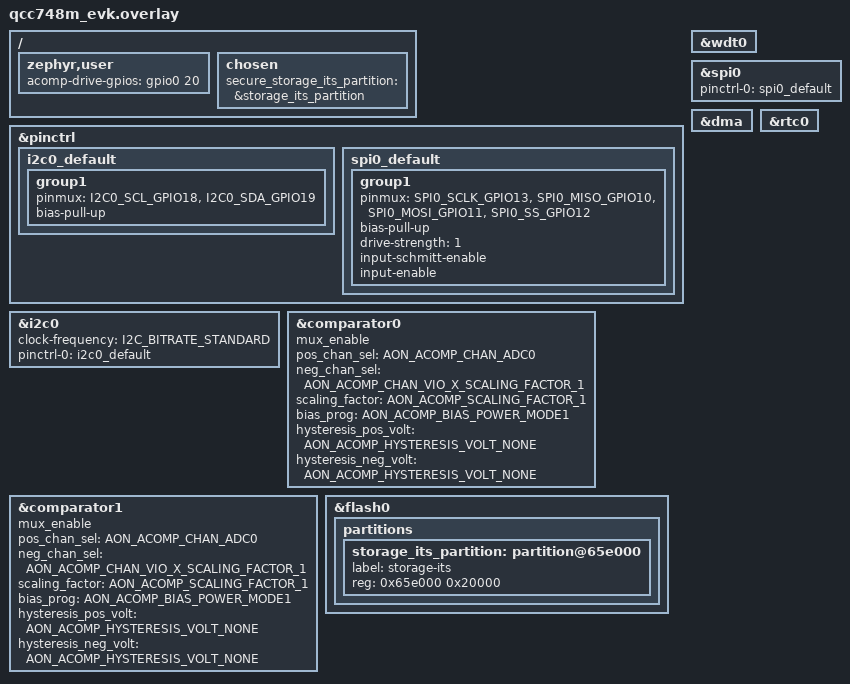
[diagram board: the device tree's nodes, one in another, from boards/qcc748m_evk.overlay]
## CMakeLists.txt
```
# Copyright (c) Qualcomm Technologies, Inc. and/or its subsidiaries
# SPDX-License-Identifier: BSD-3-Clause

cmake_minimum_required(VERSION 3.20.0)

# boards/qcc748m_evk.conf and boards/qcc748m_evk.overlay are auto-detected
# by Zephyr from this project's boards/ directory — no explicit references needed.
# All shell modules (async_test_shell, i2c_eeprom_async, crypto, flash, psram...)
# are provided by qapp/qcc74x/common/shell/ via module.yml auto-inclusion.
find_package(Zephyr REQUIRED HINTS $ENV{ZEPHYR_BASE})
project(qcli_app)

target_sources(app PRIVATE src/main.c)
```

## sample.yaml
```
# Copyright (c) Qualcomm Technologies, Inc. and/or its subsidiaries
# SPDX-License-Identifier: BSD-3-Clause

sample:
  name: QCC74x CLI App
  description: >
    Interactive CLI for QCC74x development boards. Provides shell commands
    for all on-board peripherals (I2C, SPI, CAN, PWM, ADC, DAC, GPIO,
    WDT, RTC, Counter, Comparator, Crypto, Flash, PSRAM) plus WiFi/Net.

tests:
  sample.qcli_app:
    platform_allow:
      - qcc748m_evk/qcc748
    harness: console
    harness_config:
      type: one_line
      regex:
        - "qcc74x:~\\$"
    timeout: 60
    tags:
      - shell
      - qcli_app
```

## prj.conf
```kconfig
# Copyright (c) Qualcomm Technologies, Inc. and/or its subsidiaries
# SPDX-License-Identifier: BSD-3-Clause
#
# qcli minimal conf — networking and peripheral config 
CONFIG_EARLY_CONSOLE=y

# Common shell and SPI shell support
CONFIG_SHELL=y
CONFIG_SHELL_BACKEND_SERIAL=y
CONFIG_QCOM_SPI_SHELL=y
CONFIG_SPI=y
CONFIG_SPI_SLAVE=y
```

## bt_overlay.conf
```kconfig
CONFIG_SYSTEM_WORKQUEUE_STACK_SIZE=2048
CONFIG_TEST=y
CONFIG_TEST_LOGGING_DEFAULTS=n
CONFIG_BT=y
CONFIG_LOG=y
CONFIG_BT_CENTRAL=y
CONFIG_BT_PERIPHERAL=y
CONFIG_BT_PRIVACY=y
CONFIG_BT_SMP=y
CONFIG_BT_PASSKEY_KEYPRESS=y
CONFIG_BT_APP_PASSKEY=y
CONFIG_BT_ATT_PREPARE_COUNT=2
CONFIG_BT_GATT_CLIENT=y
CONFIG_BT_L2CAP_DYNAMIC_CHANNEL=y
CONFIG_BT_SHELL=y
CONFIG_BT_DEVICE_NAME="test shell"
CONFIG_BT_DEVICE_NAME_DYNAMIC=y
CONFIG_BT_L2CAP_TX_BUF_COUNT=4
CONFIG_BT_ID_MAX=2
CONFIG_BT_EATT=y
CONFIG_BT_L2CAP_ECRED=y
CONFIG_BT_GATT_DYNAMIC_DB=y
CONFIG_BT_GATT_NOTIFY_MULTIPLE=y
CONFIG_BT_HRS=y
CONFIG_BT_FILTER_ACCEPT_LIST=y
CONFIG_BT_REMOTE_INFO=y
CONFIG_BT_REMOTE_VERSION=y
CONFIG_BT_GATT_AUTO_DISCOVER_CCC=y

CONFIG_BT_SETTINGS=y
CONFIG_FLASH=y
CONFIG_FLASH_MAP=y
CONFIG_NVS=y
CONFIG_SETTINGS=y

CONFIG_BT_EXT_ADV=y
CONFIG_BT_EXT_ADV_LEGACY_SUPPORT=y
CONFIG_BT_PER_ADV=y
CONFIG_BT_PER_ADV_SYNC=y

CONFIG_BT_USER_DATA_LEN_UPDATE=y
CONFIG_BT_AUTO_DATA_LEN_UPDATE=y

CONFIG_BT_EAD=y

CONFIG_BT_USER_PHY_UPDATE=y

CONFIG_BT_ISO_BROADCASTER=y
CONFIG_BT_ISO_SYNC_RECEIVER=y
CONFIG_BT_ISO_CENTRAL=y
CONFIG_BT_ISO_PERIPHERAL=y

CONFIG_LOG_RUNTIME_FILTERING=y

CONFIG_MINIMAL_LIBC_STRING_ERROR_TABLE=y
CONFIG_QCOM_ACOMP_SHELL=n
CONFIG_PSA_CRYPTO_ENABLE_ALL=n

CONFIG_BT_RX_STACK_SIZE=2048

# PSRAM: enable 4MB PSRAM with code-copy support on qcc748.
CONFIG_FLASH_XIP_LENGTH=0x400000
CONFIG_PSRAM=y
CONFIG_PSRAM_LENGTH=0x400000
CONFIG_PSRAM_COPY_CODE=y
```

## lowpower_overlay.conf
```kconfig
# Copyright (c) Qualcomm Technologies, Inc. and/or its subsidiaries
# SPDX-License-Identifier: BSD-3-Clause

# Default QCC748 Wi-Fi PDS15/LPFW profile for QCLI.
CONFIG_PM=y
CONFIG_PM_POLICY_CUSTOM=y
CONFIG_PM_CPU_SHELL=y
CONFIG_PM_DEVICE=y
CONFIG_PM_NEED_ALL_DEVICES_IDLE=n
CONFIG_PM_DEVICE_SYSTEM_MANAGED=y
CONFIG_GPIO=y
CONFIG_PSRAM=n
CONFIG_RISCV_MACHINE_TIMER=n
CONFIG_QCC74X_PM_PDS15=y

CONFIG_POWEROFF=y
CONFIG_QCC74X_HBN_SHELL=y
CONFIG_QCC74X_WIFI_LOW_POWER=y
CONFIG_QCC74X_PM_DIAGNOSTICS=y
CONFIG_QCC74X_PM_PDS15_LOG_LEVEL_OFF=y
CONFIG_QCC74X_PM_PDS_VALIDATION=y

CONFIG_THREAD_LOCAL_STORAGE=y
CONFIG_CURRENT_THREAD_USE_TLS=y
CONFIG_SHELL_PROMPT_UART="qcc74x:~$"
CONFIG_LOG_MODE_DEFERRED=y
CONFIG_LOG_RUNTIME_FILTERING=n
CONFIG_PRINTK=y
CONFIG_HEAP_MEM_POOL_SIZE=26624

# PDS15 has no PSRAM. Keep Wi-Fi runtime allocations within OCRAM/WRAM.
CONFIG_NET_PKT_TX_COUNT=14
CONFIG_NET_BUF_TX_COUNT=16
```

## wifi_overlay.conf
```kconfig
# ==================== Base (from wifi-shell prj.conf) ====================
CONFIG_EARLY_CONSOLE=y
CONFIG_NETWORKING=y
CONFIG_TEST_RANDOM_GENERATOR=y


CONFIG_NET_MAX_CONTEXTS=10
CONFIG_NET_DHCPV4=y

CONFIG_NET_IPV4=y
CONFIG_NET_TCP=y
CONFIG_NET_SHELL=y
CONFIG_NET_STATISTICS=y
CONFIG_NET_STATISTICS_PERIODIC_OUTPUT=n

CONFIG_WIFI=y
CONFIG_WIFI_LOG_LEVEL_ERR=y
CONFIG_NET_L2_WIFI_SHELL=y
CONFIG_NET_MGMT_EVENT_QUEUE_TIMEOUT=5000

# ==================== Network Buffers & Interfaces ====================
# Number of RX packets
CONFIG_NET_PKT_RX_COUNT=8
# Number of TX packets
CONFIG_NET_PKT_TX_COUNT=14
# Network buffer pool size (RX)
CONFIG_NET_BUF_RX_COUNT=8
# Network buffer pool size (TX)
CONFIG_NET_BUF_TX_COUNT=16
# Max IPv4 addresses per interface
CONFIG_NET_IF_MAX_IPV4_COUNT=2
# Max IPv6 addresses per interface
CONFIG_NET_IF_MAX_IPV6_COUNT=2
# Enable Ethernet L2
CONFIG_NET_L2_ETHERNET=y
CONFIG_NET_BUF_DATA_SIZE=1600
CONFIG_NET_BUF_POOL_USAGE=y
CONFIG_NET_BUF_LOG=y

CONFIG_NET_TX_STACK_SIZE=4096
CONFIG_NET_RX_STACK_SIZE=4096

CONFIG_NET_TCP_WORKQ_STACK_SIZE=2048
# ==================== Network Management ====================
# Net management event queue size
CONFIG_NET_MGMT_EVENT_QUEUE_SIZE=10
# Net management event handler stack size
CONFIG_NET_MGMT_EVENT_STACK_SIZE=8192
# Enable network connection manager
CONFIG_NET_CONNECTION_MANAGER=y
CONFIG_NET_CONNECTION_MANAGER_MONITOR_STACK_SIZE=2048

# ==================== Ethernet Driver ====================
# Keep the WiFi shell sample off the EMAC path for now.
# CONFIG_ETH_DRIVER is not set
# CONFIG_ETH_PHY_DRIVER is not set

# ==================== IPv4 & DHCPv4 ====================
# Number of DHCPv4 server addresses
CONFIG_NET_DHCPV4_SERVER_ADDR_COUNT=4
# ICMP probe timeout for DHCPv4 (ms)
CONFIG_NET_DHCPV4_SERVER_ICMP_PROBE_TIMEOUT=1000
# Enable DHCPv4 server
CONFIG_NET_DHCPV4_SERVER=y
# Enable DHCPv4 DNS address option
CONFIG_NET_DHCPV4_OPTION_DNS_ADDRESS=y
# DHCPv4 server log level: debug
CONFIG_NET_DHCPV4_SERVER_LOG_LEVEL_DBG=y

# ==================== IPv6 & DHCPv6 ====================
# Enable IPv6 protocol
CONFIG_NET_IPV6=y
# Enable RDNSS option in IPv6 RA
CONFIG_NET_IPV6_RA_RDNSS=y
# Enable DHCPv6 DNS address option
CONFIG_NET_DHCPV6_OPTION_DNS_ADDRESS=y

# ==================== Sockets & TLS/DTLS ====================
# Keep the sample on the plain sockets path on Zephyr 4.3.
# CONFIG_NET_SOCKETS_SOCKOPT_TLS is not set
# CONFIG_NET_SOCKETS_ENABLE_DTLS is not set
# DNS query timeout (ms)
CONFIG_NET_SOCKETS_DNS_TIMEOUT=2000
# DNS backoff interval (ms)
CONFIG_NET_SOCKETS_DNS_BACKOFF_INTERVAL=5000
# Enable Sockets service
CONFIG_NET_SOCKETS_SERVICE=y
# Service thread priority
CONFIG_NET_SOCKETS_SERVICE_THREAD_PRIO=15
# Service thread stack size
CONFIG_NET_SOCKETS_SERVICE_STACK_SIZE=4096

# ==================== DNS Resolver ====================
CONFIG_DNS_RESOLVER=y

# ==================== Network Test Tool ====================
# Enable zperf performance testing
CONFIG_NET_ZPERF=y
CONFIG_NET_ZPERF_SERVER=y
CONFIG_NET_ZPERF_MAX_SESSIONS=6
CONFIG_ZPERF_SESSION_PER_THREAD=y
CONFIG_ZPERF_WORK_Q_STACK_SIZE=4096
CONFIG_NET_ZPERF_MAX_PACKET_SIZE=1500

# ==================== Statistics ====================
# Enable named statistics
CONFIG_STATS_NAMES=y
# Enable stats in shell
CONFIG_STATS_SHELL=y
# Enable statistics
CONFIG_STATS=y
# Enable network statistics shell commands
CONFIG_NET_STATISTICS_USER_API=y

# ==================== WiFi Configuration ====================
# QCC74X WiFi driver
CONFIG_WIFI_QCC74X=y
# AP & STA mode support
CONFIG_QC7XX_WIFI_AP_STA_MODE=y
# STA mode auto DHCPv4
CONFIG_QC7XX_WIFI_STA_AUTO_DHCPV4=y
# WiFi network manager
CONFIG_WIFI_NM=y
# Max managed interfaces
CONFIG_WIFI_NM_MAX_MANAGED_INTERFACES=4
# Shell max AP/STA interfaces
CONFIG_WIFI_SHELL_MAX_AP_STA=4
```

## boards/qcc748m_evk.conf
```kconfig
# Copyright (c) Qualcomm Technologies, Inc. and/or its subsidiaries
# SPDX-License-Identifier: BSD-3-Clause
#
# qcc748m_evk board configuration for qcli.
# Merged from wifi-shell prj.conf + boards/qcc748m_evk.conf.


# ==================== Shell Configuration ====================
# Stack size for shell task
CONFIG_SHELL_STACK_SIZE=3072
# QCOM comparator shell validation
CONFIG_COMPARATOR=y
CONFIG_QCOM_ACOMP_SHELL=y
# Reopen / startup on this bench can deliver a short RX burst before the shell
# thread drains input, so keep more headroom than the generic default (64).
CONFIG_SHELL_BACKEND_SERIAL_RX_RING_BUFFER_SIZE=128
# Shell prompt setting
CONFIG_SHELL_PROMPT_UART="qcc74x:~$"
#not defined yet
#CONFIG_ETH_QC7XX_EMAC=n


# ==================== Threads & Workqueue ====================
# Main stack size
CONFIG_MAIN_STACK_SIZE=4096
# System workqueue stack size
CONFIG_SYSTEM_WORKQUEUE_STACK_SIZE=6144
# Dynamic threads support
CONFIG_DYNAMIC_THREAD=y
CONFIG_DYNAMIC_THREAD_ALLOC=y
CONFIG_DYNAMIC_THREAD_PREFER_POOL=y
# Runtime statistics
CONFIG_THREAD_RUNTIME_STATS=y
CONFIG_THREAD_RUNTIME_STATS_USE_TIMING_FUNCTIONS=y
# Thread info & monitoring
CONFIG_THREAD_STACK_INFO=y
CONFIG_THREAD_MONITOR=y
CONFIG_THREAD_NAME=y
CONFIG_THREAD_CUSTOM_DATA=y
# Initialize all thread stacks
CONFIG_INIT_STACKS=y

# ==================== Memory & Heap ====================
# Heap memory pool size
CONFIG_HEAP_MEM_POOL_SIZE=32708
# Sys heap runtime stats
CONFIG_SYS_HEAP_RUNTIME_STATS=y
# Shared multi-heap support
CONFIG_SHARED_MULTI_HEAP=y
# ==================== mbedTLS / PSA Crypto ====================
# Zephyr 4.3 moved most legacy mbedTLS feature toggles behind PSA wants.
# Keep TLS sockets disabled above, but still link the crypto pieces used
# by the QC7XX wireless HAL blob.
CONFIG_MBEDTLS=y
# Use QCC74x soc_multi_heap via mbedtls_platform_set_calloc_free().
# CONFIG_MBEDTLS_ENABLE_HEAP is not set
CONFIG_MBEDTLS_PSA_STATIC_KEY_SLOTS=n
CONFIG_PSA_CRYPTO=y
CONFIG_PSA_CRYPTO_PROVIDER_MBEDTLS=y
CONFIG_PSA_WANT_KEY_TYPE_ECC_PUBLIC_KEY=y
CONFIG_PSA_WANT_ECC_SECP_R1_256=y
CONFIG_PSA_WANT_ALG_ECDH=y
CONFIG_PSA_WANT_ALG_ECDSA=y
CONFIG_PSA_WANT_KEY_TYPE_AES=y
CONFIG_PSA_WANT_ALG_ECB_NO_PADDING=y
CONFIG_MBEDTLS_ASN1_PARSE_C=y
CONFIG_MBEDTLS_MD_C=y
CONFIG_MBEDTLS_ENTROPY_C=y
CONFIG_MBEDTLS_CTR_DRBG_C=y
CONFIG_MBEDTLS_PSA_CRYPTO_LEGACY_RNG=y
CONFIG_MBEDTLS_PK_WRITE_C=y
CONFIG_MBEDTLS_PKCS5_C=y
CONFIG_MBEDTLS_PEM_PARSE_C=y
CONFIG_MBEDTLS_ECP_NIST_OPTIM=y
CONFIG_MBEDTLS_AES_ROM_TABLES=y

# ==================== CRC & File System ====================
CONFIG_CRC=y
CONFIG_ZVFS_POLL_MAX=15

# ==================== Logging & Commands ====================
CONFIG_LOG=y
# Enable log commands
CONFIG_LOG_CMDS=y
CONFIG_NET_LOG=y

CONFIG_NET_CONFIG_LOG_LEVEL_DBG=y

# ==================== QCC748M Coredump Profiles ====================
# Common support for every mode. Keep these settings enabled when switching
# profiles: the QCC74x runtime performs the post-dump software reset.
CONFIG_DEBUG_COREDUMP=y
CONFIG_QCC74X_COREDUMP_RUNTIME=y
CONFIG_QCC74X_COREDUMP_AUTO_RESET=y
CONFIG_QCC74X_COREDUMP_TEST_COMMANDS=y
#
# Select exactly one mode below. Mode 0 is the default.
#
# MODE 0 (default): Zephyr native minimal coredump through the normal logging
# backend. It preserves Zephyr's basic payload and resets after output drains.
CONFIG_DEBUG_COREDUMP_BACKEND_LOGGING=y
CONFIG_DEBUG_COREDUMP_MEMORY_DUMP_MIN=y
#
# To select Mode 1, 2, or 3: comment out the two active MODE 0 settings above,
# then uncomment all settings in exactly one block below. Do not change the
# common support settings.
#
# MODE 1: serial_full_psram
# Full OCRAM/WRAM/PSRAM dump through the safe serial backend. For practical
# full-PSRAM capture, also enable the optional 2 Mbaud UART0 overlay block.
# CONFIG_DEBUG_COREDUMP_BACKEND_OTHER=y
# CONFIG_DEBUG_COREDUMP_MEMORY_DUMP_LINKER_RAM=y
# CONFIG_PSRAM_LENGTH=0x800000
# CONFIG_QCC74X_COREDUMP_FULL_MEMORY=y
# CONFIG_QCC74X_COREDUMP_OTHER_SAFE_SERIAL=y
# CONFIG_QCC74X_COREDUMP_SERIAL_FULL_PSRAM=y
#
# MODE 2: flash_tracked_psram
# Full static RAM plus tracked active PSRAM allocations stored in the 1.5 MiB
# coredump Flash partition. Also enable the Mode 2 Flash partition overlay.
# CONFIG_FLASH=y
# CONFIG_DEBUG_COREDUMP_BACKEND_OTHER=y
# CONFIG_DEBUG_COREDUMP_MEMORY_DUMP_LINKER_RAM=y
# CONFIG_PSRAM_LENGTH=0x800000
# CONFIG_QCC74X_COREDUMP_FULL_MEMORY=y
# CONFIG_QCC74X_COREDUMP_OTHER_SAFE_FLASH=y
# CONFIG_QCC74X_COREDUMP_SERIAL_TRACKED_PSRAM=y
#
# MODE 3: serial_tracked_psram
# Full static RAM plus tracked active PSRAM allocations through the safe
# serial backend at the normal console baud rate.
# CONFIG_DEBUG_COREDUMP_BACKEND_OTHER=y
# CONFIG_DEBUG_COREDUMP_MEMORY_DUMP_LINKER_RAM=y
# CONFIG_PSRAM_LENGTH=0x800000
# CONFIG_QCC74X_COREDUMP_FULL_MEMORY=y
# CONFIG_QCC74X_COREDUMP_OTHER_SAFE_SERIAL=y
# CONFIG_QCC74X_COREDUMP_SERIAL_TRACKED_PSRAM=y
#
# `qcom coredump ...` shell support is selected automatically by the QCC74x
# runtime. Zephyr's independent CONFIG_DEBUG_COREDUMP_SHELL is not required.
# The following generic debug features remain available independently of
# coredump and are intentionally not part of any coredump profile.
CONFIG_SYMTAB=y
CONFIG_SYMTAB_SHELL=y
CONFIG_TRACING=y
CONFIG_DEBUG_THREAD_INFO=n
CONFIG_THREAD_ANALYZER=y

# ==================== POSIX Support ====================
CONFIG_POSIX_API=y
CONFIG_POSIX_TIMERS=y
CONFIG_REQUIRES_FLOAT_PRINTF=y
CONFIG_PICOLIBC_IO_FLOAT=y

# ==================== Miscellaneous ====================
# Reboot support
CONFIG_REBOOT=y

# Watchdog support: expose the native Zephyr WDT shell for diagnosis.
CONFIG_WATCHDOG=y
CONFIG_WDT_SHELL=y
CONFIG_WDT_DISABLE_AT_BOOT=n

# Kernel / PM / HW Info
CONFIG_KERNEL_SHELL=y
CONFIG_HWINFO=y
CONFIG_HWINFO_SHELL=y
# Settings
CONFIG_SETTINGS=y
CONFIG_SETTINGS_SHELL=y


# ==================== Peripheral Shells ====================
# Async shell execution
CONFIG_QCOM_SHELL_ASYNC=y
CONFIG_SHELL_ASYNC_STACK_SIZE=2048

# I2C
CONFIG_I2C=y
CONFIG_QCOM_I2C_SHELL=y

# RTC
CONFIG_RTC=y
CONFIG_RTC_SHELL=y

# ==================== Secure Storage (PSA ITS) ====================
CONFIG_SECURE_STORAGE=y
CONFIG_SECURE_STORAGE_ITS_IMPLEMENTATION_ZEPHYR=y
CONFIG_SECURE_STORAGE_ITS_STORE_IMPLEMENTATION_ZMS=y
CONFIG_SECURE_STORAGE_ITS_TRANSFORM_MODULE=y
CONFIG_SECURE_STORAGE_ITS_TRANSFORM_IMPLEMENTATION_AEAD=y
CONFIG_SECURE_STORAGE_ITS_TRANSFORM_AEAD_SCHEME_AES_GCM=y
CONFIG_SECURE_STORAGE_ITS_TRANSFORM_AEAD_KEY_PROVIDER_ENTRY_UID_HASH=y
CONFIG_SECURE_STORAGE_ITS_TRANSFORM_AEAD_NONCE_PROVIDER_DEFAULT=y
CONFIG_SECURE_STORAGE_ITS_TRANSFORM_AEAD_KEY_SIZE=32
CONFIG_SECURE_STORAGE_ITS_TRANSFORM_AEAD_NONCE_SIZE=12
CONFIG_SECURE_STORAGE_ITS_MAX_DATA_SIZE=128
CONFIG_ZMS=y
CONFIG_FLASH=y
CONFIG_FLASH_MAP=y
CONFIG_SOC_FLASH_QCC74X=y
```

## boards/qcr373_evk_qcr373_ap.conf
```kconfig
# Copyright (c) Qualcomm Technologies, Inc. and/or its subsidiaries
# SPDX-License-Identifier: BSD-3-Clause

CONFIG_SHELL=y
CONFIG_SHELL_MINIMAL=n
CONFIG_CONSOLE=y
CONFIG_UART_CONSOLE=y
CONFIG_LOG=y
CONFIG_LOG_MODE_IMMEDIATE=y
CONFIG_SYS_HEAP_RUNTIME_STATS=y
CONFIG_HEAP_MEM_POOL_SIZE=16384
CONFIG_QCOM_SPI_SHELL=n
```

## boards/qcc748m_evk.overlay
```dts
/*
 * Copyright (c) Qualcomm Technologies, Inc. and/or its subsidiaries
 * SPDX-License-Identifier: BSD-3-Clause
 *
 */

#include <zephyr/dt-bindings/pinctrl/qc7xx-qcc74x-pinctrl.h>
#include <zephyr/dt-bindings/dma/qcc74x_dma.h>
/* ------------------------------------------------------------------ */
/*  Pinctrl states                                                       */
/* ------------------------------------------------------------------ */
&pinctrl {
	/* I2C0: GPIO18=SCL, GPIO19=SDA */
	i2c0_default: i2c0_default {
		group1 {
			pinmux = <I2C0_SCL_GPIO18>, <I2C0_SDA_GPIO19>;
			bias-pull-up;
		};
	};
};

/* ------------------------------------------------------------------ */
/*  Peripheral nodes — diagnosis mode: only i2c0 enabled               */
/* ------------------------------------------------------------------ */

&i2c0 {
	status = "okay";
	clock-frequency = <I2C_BITRATE_STANDARD>;
	pinctrl-0 = <&i2c0_default>;
	pinctrl-names = "default";
};

/* SPI0: GPIO13=SCLK, GPIO10=MISO, GPIO11=MOSI, GPIO12=SS */
&pinctrl {
	spi0_default: spi0_default {
		group1 {
			pinmux = <SPI0_SCLK_GPIO13>,
				<SPI0_MISO_GPIO10>,
				<SPI0_MOSI_GPIO11>,
				<SPI0_SS_GPIO12>;
			bias-pull-up;
			drive-strength = <1>;
			input-schmitt-enable;
			input-enable;
		};
	};
};

&wdt0 {
	status = "okay";
};

/* Optional coredump profiles. Default QCLI uses Mode 0 at 115200 baud. */

/* Mode 1 full-dump testing: manually enable UART0 2 Mbaud before building. */
/*
&uart0 {
	current-speed = <2000000>;
	clocks = <&clock0 QC7XX_PERIPHERAL_UART0 QC7XX_UART_CLK_MUXPLL_160M>;
};
*/

&spi0 {
	status = "okay";
	pinctrl-0 = <&spi0_default>;
	pinctrl-names = "default";
};

&dma {
	status = "okay";
};

/* Mode 2: flash_tracked_psram (1.5 MiB coredump slot). */
/*
/delete-node/ &coredump_partition;

&flash0 {
	partitions {
		coredump_partition: partition@67e000 {
			label = "coredump-partition";
			reg = <0x67e000 0x180000>;
		};
	};
};
*/

/* Mode 3: serial_tracked_psram needs no DeviceTree change. */

/* Optional watchdog coordination when QCLI installs and feeds wdt0. */
/*
&wdt0 {
	status = "okay";
};
*/

/ {
	zephyr,user {
		acomp-drive-gpios = <&gpio0 20 GPIO_ACTIVE_HIGH>;
	};
};

&comparator0 {
	status = "okay";
	mux_enable;
	pos_chan_sel = "AON_ACOMP_CHAN_ADC0";
	neg_chan_sel = "AON_ACOMP_CHAN_VIO_X_SCALING_FACTOR_1";
	scaling_factor = "AON_ACOMP_SCALING_FACTOR_1";
	bias_prog = "AON_ACOMP_BIAS_POWER_MODE1";
	hysteresis_pos_volt = "AON_ACOMP_HYSTERESIS_VOLT_NONE";
	hysteresis_neg_volt = "AON_ACOMP_HYSTERESIS_VOLT_NONE";
};

&comparator1 {
	status = "okay";
	mux_enable;
	pos_chan_sel = "AON_ACOMP_CHAN_ADC0";
	neg_chan_sel = "AON_ACOMP_CHAN_VIO_X_SCALING_FACTOR_1";
	scaling_factor = "AON_ACOMP_SCALING_FACTOR_1";
	bias_prog = "AON_ACOMP_BIAS_POWER_MODE1";
	hysteresis_pos_volt = "AON_ACOMP_HYSTERESIS_VOLT_NONE";
	hysteresis_neg_volt = "AON_ACOMP_HYSTERESIS_VOLT_NONE";
};

&rtc0 {
	status = "okay";
};

/* Secure Storage ITS Partition */
/ {
	chosen {
		secure_storage_its_partition = &storage_its_partition;
	};
};

&flash0 {
	partitions {
		storage_its_partition: partition@65e000 {
			label = "storage-its";
			reg = <0x65e000 0x20000>;
		};
	};
};
```

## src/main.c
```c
/*
 * Copyright (c) Qualcomm Technologies, Inc. and/or its subsidiaries
 * SPDX-License-Identifier: BSD-3-Clause
 *
 * qcli — QCC7xx CLI application entry point.
 *
 */

int main(void)
{
	return 0;
}
```
